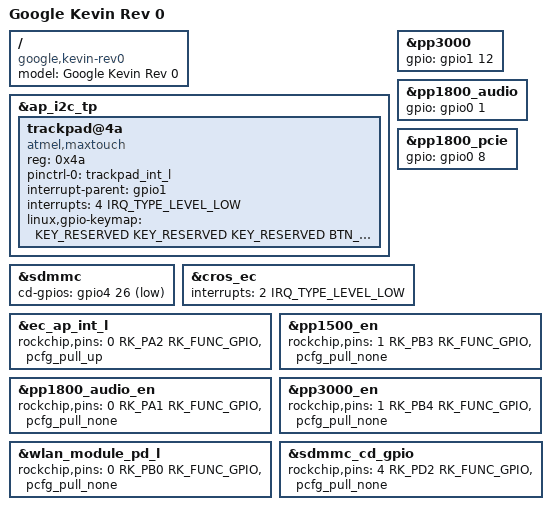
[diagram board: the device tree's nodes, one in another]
/*
 * Google Gru-Kevin Rev 0 board device tree source
 *
 * Copyright 2016 Google, Inc
 *
 * This file is dual-licensed: you can use it either under the terms
 * of the GPL or the X11 license, at your option. Note that this dual
 * licensing only applies to this file, and not this project as a
 * whole.
 *
 *  a) This file is free software; you can redistribute it and/or
 *     modify it under the terms of the GNU General Public License as
 *     published by the Free Software Foundation; either version 2 of the
 *     License, or (at your option) any later version.
 *
 *     This file is distributed in the hope that it will be useful,
 *     but WITHOUT ANY WARRANTY; without even the implied warranty of
 *     MERCHANTABILITY or FITNESS FOR A PARTICULAR PURPOSE.  See the
 *     GNU General Public License for more details.
 *
 *  Or, alternatively,
 *
 *  b) Permission is hereby granted, free of charge, to any person
 *     obtaining a copy of this software and associated documentation
 *     files (the "Software"), to deal in the Software without
 *     restriction, including without limitation the rights to use,
 *     copy, modify, merge, publish, distribute, sublicense, and/or
 *     sell copies of the Software, and to permit persons to whom the
 *     Software is furnished to do so, subject to the following
 *     conditions:
 *
 *     The above copyright notice and this permission notice shall be
 *     included in all copies or substantial portions of the Software.
 *
 *     THE SOFTWARE IS PROVIDED "AS IS", WITHOUT WARRANTY OF ANY KIND,
 *     EXPRESS OR IMPLIED, INCLUDING BUT NOT LIMITED TO THE WARRANTIES
 *     OF MERCHANTABILITY, FITNESS FOR A PARTICULAR PURPOSE AND
 *     NONINFRINGEMENT. IN NO EVENT SHALL THE AUTHORS OR COPYRIGHT
 *     HOLDERS BE LIABLE FOR ANY CLAIM, DAMAGES OR OTHER LIABILITY,
 *     WHETHER IN AN ACTION OF CONTRACT, TORT OR OTHERWISE, ARISING
 *     FROM, OUT OF OR IN CONNECTION WITH THE SOFTWARE OR THE USE OR
 *     OTHER DEALINGS IN THE SOFTWARE.
 */

/dts-v1/;
#include "rk3399-gru.dtsi"

/ {
	model = "Google Kevin Rev 0";
	compatible = "google,kevin-rev0",
		     "google,kevin", "google,gru", "rockchip,rk3399";
};

&ap_i2c_tp {
	trackpad@4a {
		compatible = "atmel,maxtouch";
		reg = <0x4a>;
		pinctrl-names = "default";
		pinctrl-0 = <&trackpad_int_l>;
		interrupt-parent = <&gpio1>;
		interrupts = <4 IRQ_TYPE_LEVEL_LOW>;
		linux,gpio-keymap = <KEY_RESERVED
				     KEY_RESERVED
				     KEY_RESERVED
				     BTN_LEFT>;
	};
};

/* GPIO overrides for -r0; in same order as parent */

&pp3000 {
	gpio = <&gpio1 12 GPIO_ACTIVE_HIGH>;
};

&pp1800_audio {
	gpio = <&gpio0 1 GPIO_ACTIVE_HIGH>;
};

&pp1800_pcie {
	gpio = <&gpio0 8 GPIO_ACTIVE_HIGH>;
};

&sdmmc {
	cd-gpios = <&gpio4 26 GPIO_ACTIVE_LOW>;
};

&cros_ec {
	interrupts = <2 IRQ_TYPE_LEVEL_LOW>;
};

/* Pinctrl overrides for -r0; in same order as parent */

&ec_ap_int_l {
	rockchip,pins = <0 RK_PA2 RK_FUNC_GPIO &pcfg_pull_up>;
};

&pp1500_en {
	rockchip,pins = <1 RK_PB3 RK_FUNC_GPIO &pcfg_pull_none>;
};

&pp1800_audio_en {
	rockchip,pins = <0 RK_PA1 RK_FUNC_GPIO
			 &pcfg_pull_none>;
};

&pp3000_en {
	rockchip,pins = <1 RK_PB4 RK_FUNC_GPIO
			 &pcfg_pull_none>;
};

&wlan_module_pd_l {
	rockchip,pins = <0 RK_PB0 RK_FUNC_GPIO
			 &pcfg_pull_none>;
};

&sdmmc_cd_gpio {
	rockchip,pins = <4 RK_PD2 RK_FUNC_GPIO &pcfg_pull_none>;
};
